# STM32F410CBU7 register map
File version: 1.0
STM32F410C8T3,STM32F410C8T6,STM32F410C8T7,STM32F410C8U6,STM32F410C8U7,STM32F410CBT3,STM32F410CBT6,STM32F410CBT7,STM32F410CBU3,STM32F410CBU6,STM32F410CBU7
Registers are 32-bit, access not given, reset 0x0 unless marked. A register's access mark holds for its fields unless they carry their own. Offsets are from the block's base; lines under a group give offsets from that group; [hi:lo] are bit positions; {n}, {i} and the like mark numbered series; 'fields as' and 'values as' point back to an identical list; <NAME> marks a mode.

## Memory map
0x40000C00 TIM5
0x40001000 TIM6
0x40002400 LPTIM1
0x40002800 RTC
0x40002C00 WWDG
0x40003000 IWDG
0x40003800 SPI2
0x40004400 USART2
0x40005400 I2C1
0x40005800 I2C2
0x40006000 FMPI2C1
0x40007000 PWR
0x40007400 DAC1
0x40010000 TIM1
0x40011000 USART1
0x40011400 USART6
0x40012000 ADC1
0x40013000 SPI1
0x40013800 SYSCFG
0x40013C00 EXTI
0x40014000 TIM9
0x40014800 TIM11
0x40015000 SPI5
0x40020000 GPIOA
0x40020400 GPIOB
0x40020800 GPIOC
0x40021C00 GPIOH
0x40023000 CRC
0x40023800 RCC
0x40023C00 FLASH
0x40026000 DMA1
0x40026400 DMA2
0x40080000 RNG
0xE0042000 DBGMCU

## TIM5
Base 0x40000C00
Same registers: TIM6 0x40001000, TIM1 0x40010000, TIM9 0x40014000, TIM11 0x40014800
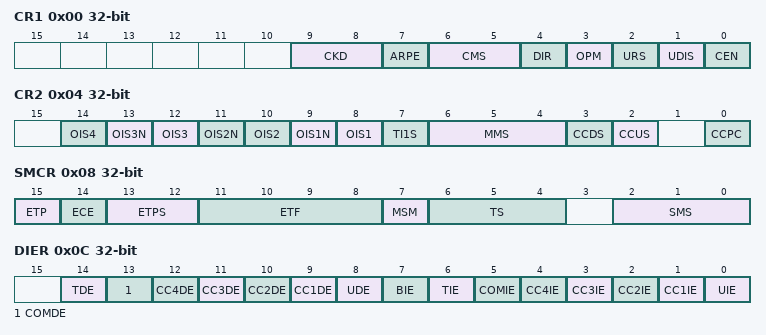
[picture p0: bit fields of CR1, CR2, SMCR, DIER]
0x00 CR1
  [9:8] CKD, [7] ARPE, [6:5] CMS, [4] DIR, [3] OPM, [2] URS, [1] UDIS, [0] CEN
0x04 CR2
  [2n+6] OIS{n} (n=1..4), [13] OIS3N, [11] OIS2N, [9] OIS1N, [7] TI1S, [6:4] MMS, [3] CCDS, [2] CCUS, [0] CCPC
0x08 SMCR
  [15] ETP, [14] ECE, [13:12] ETPS, [11:8] ETF, [7] MSM, [6:4] TS, [2:0] SMS
0x0C DIER
  [14] TDE, [13] COMDE, [n+8] CC{n}DE (n=1..4), [8] UDE, [7] BIE, [6] TIE, [5] COMIE, [n] CC{n}IE (n=1..4), [0] UIE
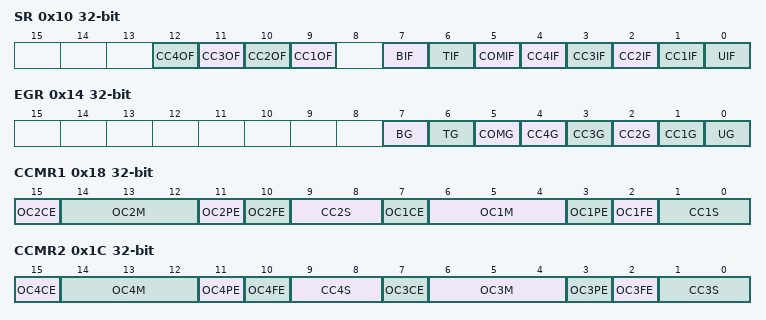
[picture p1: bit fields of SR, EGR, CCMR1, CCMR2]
0x10 SR
  [n+8] CC{n}OF (n=1..4), [7] BIF, [6] TIF, [5] COMIF, [n] CC{n}IF (n=1..4), [0] UIF
0x14 EGR
  [7] BG, [6] TG, [5] COMG, [n] CC{n}G (n=1..4), [0] UG
0x18 CCMR1
  [15] OC2CE, [14:12] OC2M, [11] OC2PE, [10] OC2FE, [9:8] CC2S, [7] OC1CE, [6:4] OC1M, [3] OC1PE, [2] OC1FE, [1:0] CC1S
0x1C CCMR2
  [15] OC4CE, [14:12] OC4M, [11] OC4PE, [10] OC4FE, [9:8] CC4S, [7] OC3CE, [6:4] OC3M, [3] OC3PE, [2] OC3FE, [1:0] CC3S
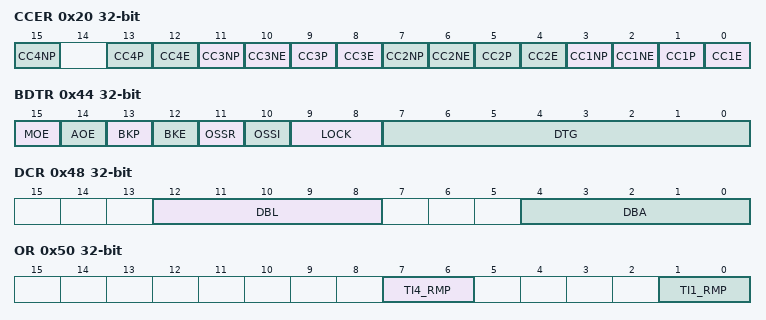
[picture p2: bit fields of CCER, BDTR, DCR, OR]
0x20 CCER
  [4n-1] CC{n}NP (n=1..4), [4n-3] CC{n}P (n=1..4), [4n-4] CC{n}E (n=1..4), [10] CC3NE, [6] CC2NE, [2] CC1NE
0x24 CNT
0x28 PSC
  [15:0] PSC
0x2C ARR
0x30 RCR
  [7:0] REP
{0x30+4i} CCR{i} (i=1..4)
  [15:0] CCR{i}
0x44 BDTR
  [15] MOE, [14] AOE, [13] BKP, [12] BKE, [11] OSSR, [10] OSSI, [9:8] LOCK, [7:0] DTG
0x48 DCR
  [12:8] DBL, [4:0] DBA
0x4C DMAR
  [15:0] DMAB
0x50 OR
  [7:6] TI4_RMP, [1:0] TI1_RMP

## LPTIM1
Base 0x40002400
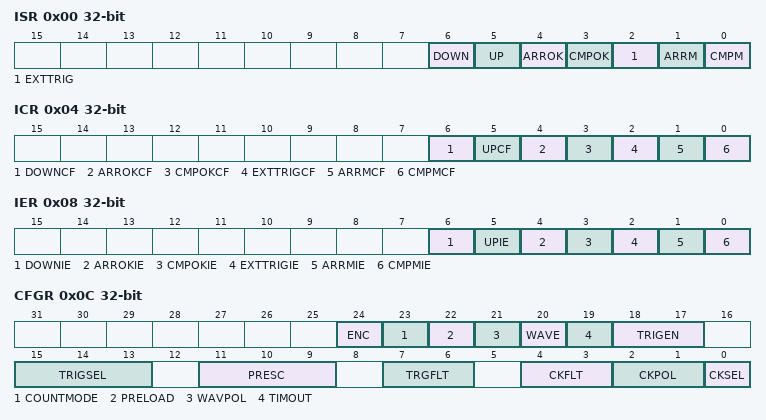
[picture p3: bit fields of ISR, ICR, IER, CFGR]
0x00 ISR
  [6] DOWN, [5] UP, [4] ARROK, [3] CMPOK, [2] EXTTRIG, [1] ARRM, [0] CMPM
0x04 ICR
  [6] DOWNCF, [5] UPCF, [4] ARROKCF, [3] CMPOKCF, [2] EXTTRIGCF, [1] ARRMCF, [0] CMPMCF
0x08 IER
  [6] DOWNIE, [5] UPIE, [4] ARROKIE, [3] CMPOKIE, [2] EXTTRIGIE, [1] ARRMIE, [0] CMPMIE
0x0C CFGR
  [24] ENC, [23] COUNTMODE, [22] PRELOAD, [21] WAVPOL, [20] WAVE, [19] TIMOUT, [18:17] TRIGEN, [15:13] TRIGSEL, [11:9] PRESC, [7:6] TRGFLT, [4:3] CKFLT, [2:1] CKPOL, [0] CKSEL
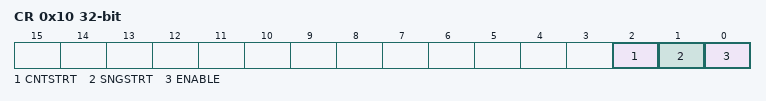
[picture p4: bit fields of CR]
0x10 CR
  [2] CNTSTRT, [1] SNGSTRT, [0] ENABLE
0x14 CMP
  [15:0] CMP
0x18 ARR
  [15:0] ARR
0x1C CNT
  [15:0] CNT
0x20 OR
  [1:0] LPT_IN1_RMP

## RTC
Base 0x40002800
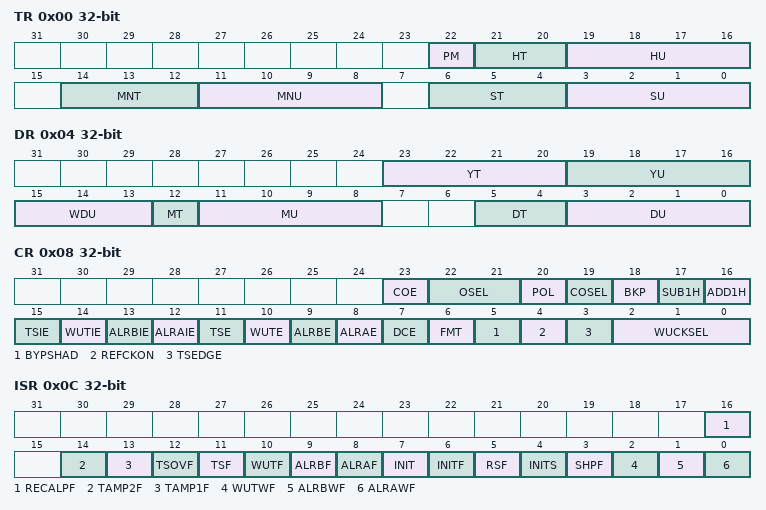
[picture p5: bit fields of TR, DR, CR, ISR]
0x00 TR
  [22] PM, [21:20] HT, [19:16] HU, [14:12] MNT, [11:8] MNU, [6:4] ST, [3:0] SU
0x04 DR
  [23:20] YT, [19:16] YU, [15:13] WDU, [12] MT, [11:8] MU, [5:4] DT, [3:0] DU
0x08 CR
  [23] COE, [22:21] OSEL, [20] POL, [19] COSEL, [18] BKP, [17] SUB1H, [16] ADD1H, [15] TSIE, [14] WUTIE, [13] ALRBIE, [12] ALRAIE, [11] TSE, [10] WUTE, [9] ALRBE, [8] ALRAE, [7] DCE, [6] FMT, [5] BYPSHAD, [4] REFCKON, [3] TSEDGE, [2:0] WUCKSEL
0x0C ISR
  [16] RECALPF, [14] TAMP2F, [13] TAMP1F, [12] TSOVF, [11] TSF, [10] WUTF, [9] ALRBF, [8] ALRAF, [7] INIT, [6] INITF, [5] RSF, [4] INITS, [3] SHPF, [2] WUTWF, [1] ALRBWF, [0] ALRAWF
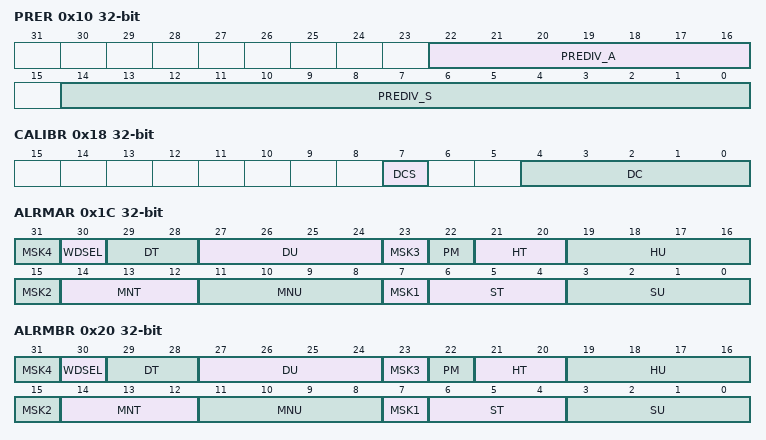
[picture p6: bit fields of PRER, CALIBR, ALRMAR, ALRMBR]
0x10 PRER
  [22:16] PREDIV_A, [14:0] PREDIV_S
0x14 WUTR
  [15:0] WUT
0x18 CALIBR
  [7] DCS, [4:0] DC
0x1C ALRMAR
  [8n-1] MSK{n} (n=1..4), [30] WDSEL, [29:28] DT, [27:24] DU, [22] PM, [21:20] HT, [19:16] HU, [14:12] MNT, [11:8] MNU, [6:4] ST, [3:0] SU
0x20 ALRMBR
  fields as ALRMAR
0x24 WPR
  [7:0] KEY
0x28 SSR
  [15:0] SS
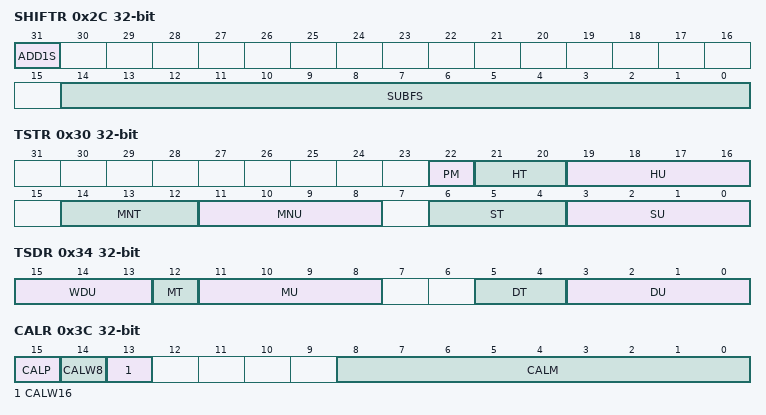
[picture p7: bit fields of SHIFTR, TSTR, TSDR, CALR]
0x2C SHIFTR
  [31] ADD1S, [14:0] SUBFS
0x30 TSTR
  fields as TR
0x34 TSDR
  [15:13] WDU, [12] MT, [11:8] MU, [5:4] DT, [3:0] DU
0x38 TSSSR
  [15:0] SS
0x3C CALR
  [15] CALP, [14] CALW8, [13] CALW16, [8:0] CALM
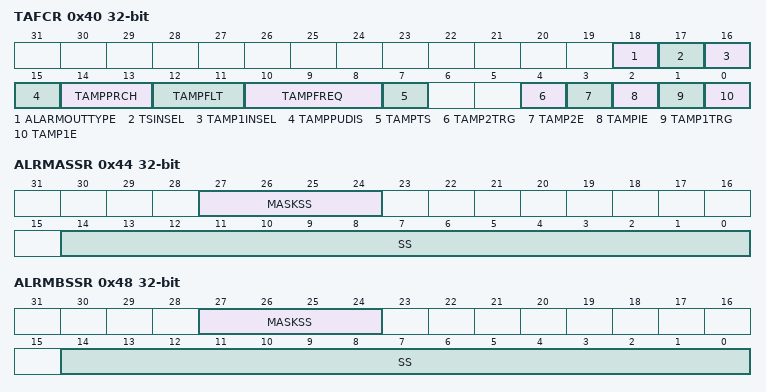
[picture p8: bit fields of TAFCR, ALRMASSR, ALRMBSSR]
0x40 TAFCR
  [18] ALARMOUTTYPE, [17] TSINSEL, [16] TAMP1INSEL, [15] TAMPPUDIS, [14:13] TAMPPRCH, [12:11] TAMPFLT, [10:8] TAMPFREQ, [7] TAMPTS, [4] TAMP2TRG, [3] TAMP2E, [2] TAMPIE, [1] TAMP1TRG, [0] TAMP1E
0x44 ALRMASSR
  [27:24] MASKSS, [14:0] SS
0x48 ALRMBSSR
  [27:24] MASKSS, [14:0] SS
{0x50+4i} BKP{i}R (i=0..19)
